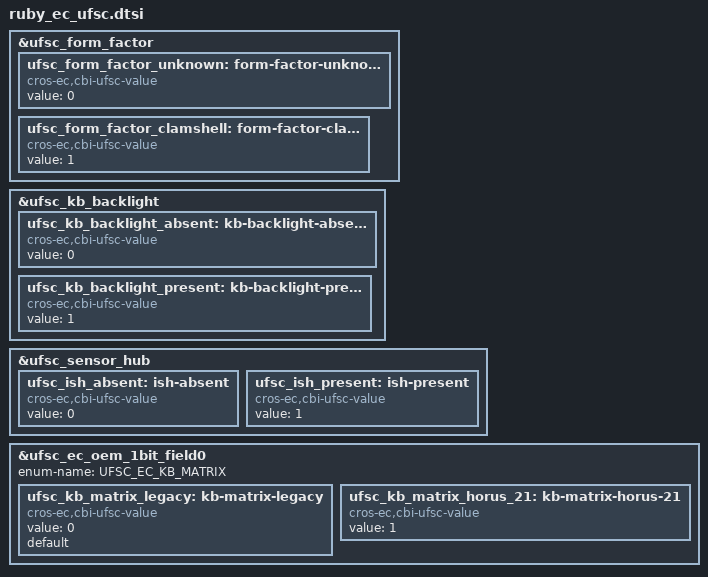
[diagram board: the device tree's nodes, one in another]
/* Auto-generated by generate_ufsc.py */

&ufsc_form_factor {
	ufsc_form_factor_unknown: form-factor-unknown {
		compatible = "cros-ec,cbi-ufsc-value";
		status = "okay";
		value = <0>;
	};
	ufsc_form_factor_clamshell: form-factor-clamshell {
		compatible = "cros-ec,cbi-ufsc-value";
		status = "okay";
		value = <1>;
	};
};

&ufsc_kb_backlight {
	ufsc_kb_backlight_absent: kb-backlight-absent {
		compatible = "cros-ec,cbi-ufsc-value";
		status = "okay";
		value = <0>;
	};
	ufsc_kb_backlight_present: kb-backlight-present {
		compatible = "cros-ec,cbi-ufsc-value";
		status = "okay";
		value = <1>;
	};
};

&ufsc_sensor_hub {
	ufsc_ish_absent: ish-absent {
		compatible = "cros-ec,cbi-ufsc-value";
		status = "okay";
		value = <0>;
	};
	ufsc_ish_present: ish-present {
		compatible = "cros-ec,cbi-ufsc-value";
		status = "okay";
		value = <1>;
	};
};

&ufsc_ec_oem_1bit_field0 {
	status = "okay";
	enum-name = "UFSC_EC_KB_MATRIX";

	ufsc_kb_matrix_legacy: kb-matrix-legacy {
		compatible = "cros-ec,cbi-ufsc-value";
		status = "okay";
		value = <0>;
		default;
	};
	ufsc_kb_matrix_horus_21: kb-matrix-horus-21 {
		compatible = "cros-ec,cbi-ufsc-value";
		status = "okay";
		value = <1>;
	};
};
